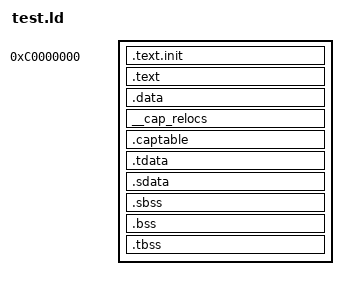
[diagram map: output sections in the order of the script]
/*======================================================================*/
/* Proxy kernel linker script                                           */
/*======================================================================*/
/* This is the linker script used when building the proxy kernel. */

/*----------------------------------------------------------------------*/
/* Setup                                                                */
/*----------------------------------------------------------------------*/

/* The OUTPUT_ARCH command specifies the machine architecture where the
   argument is one of the names used in the BFD library. More
   specifically one of the entires in bfd/cpu-mips.c */

OUTPUT_ARCH( "riscv" )
ENTRY(_start)

/*----------------------------------------------------------------------*/
/* Sections                                                             */
/*----------------------------------------------------------------------*/

SECTIONS
{

  /* text: test code section */
  . = 0xC0000000;
  .text.init : { *(.text.init) }

  .text : { *(.text) }

  /* data segment */
  .data : { *(.data) }

  __cap_relocs : {
     . = ALIGN(8);
  }

  .captable : {
     . = ALIGN(8);
  }

  /* thread-local data segment */
  .tdata :
  {
    ALIGN(8);
    _tls_data = .;
    *(.tdata.begin)
    *(.tdata)
    *(.tdata.end)
  }

  .sdata : {
    __global_pointer$ = . + 0x800;
    *(.srodata.cst16) *(.srodata.cst8) *(.srodata.cst4) *(.srodata.cst2) *(.srodata*)
    *(.sdata .sdata.* .gnu.linkonce.s.*)
  }

  /* bss segment */
  .sbss : {
    *(.sbss .sbss.* .gnu.linkonce.sb.*)
    *(.scommon)
  }
  .bss : { *(.bss) }
  .tbss :
  {
    *(.tbss)
    *(.tbss.end)
    _end = .;
  }

  /* End of uninitalized data segement */
}

